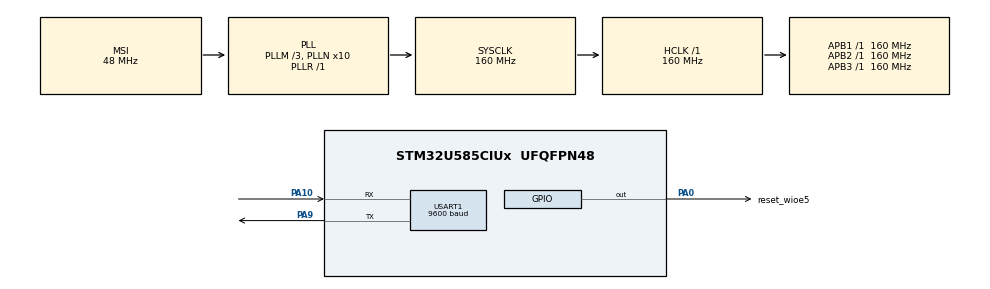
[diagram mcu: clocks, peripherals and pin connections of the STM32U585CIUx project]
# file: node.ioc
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CORTEX_M33_NS.userName=CORTEX_M33
Mcu.Family=STM32U5
Mcu.Name=STM32U585CIUx
Mcu.Package=UFQFPN48
NVIC.PriorityGroup=NVIC_PRIORITYGROUP_4
NVIC.RTC_IRQn=true\:0\:0\:false\:false\:true\:true\:true\:true
NVIC.USART1_IRQn=true\:0\:0\:false\:false\:true\:true\:true\:true
PA0.GPIO_Label=reset_wioe5
PA0.GPIO_ModeDefaultOutputPP=GPIO_MODE_OUTPUT_OD
PA0.GPIO_PuPd=GPIO_NOPULL
PA0.PinState=GPIO_PIN_RESET
PA0.Signal=GPIO_Output
PA10.GPIO_PuPd=GPIO_PULLUP
PA10.Mode=Asynchronous
PA10.Signal=USART1_RX
PA13\ (JTMS/SWDIO).Mode=Serial_Wire
PA13\ (JTMS/SWDIO).Signal=DEBUG_JTMS-SWDIO
PA14\ (JTCK/SWCLK).Mode=Serial_Wire
PA14\ (JTCK/SWCLK).Signal=DEBUG_JTCK-SWCLK
PA9.GPIO_PuPd=GPIO_PULLUP
PA9.Mode=Asynchronous
PA9.Signal=USART1_TX
PC14-OSC32_IN\ (PC14).Mode=LSE-External-Oscillator
PC14-OSC32_IN\ (PC14).Signal=RCC_OSC32_IN
PC15-OSC32_OUT\ (PC15).Mode=LSE-External-Oscillator
PC15-OSC32_OUT\ (PC15).Signal=RCC_OSC32_OUT
PH0-OSC_IN\ (PH0).Mode=HSE-External-Oscillator
PH0-OSC_IN\ (PH0).Signal=RCC_OSC_IN
PH1-OSC_OUT\ (PH1).Mode=HSE-External-Oscillator
PH1-OSC_OUT\ (PH1).Signal=RCC_OSC_OUT
ProjectManager.HeapSize=0x200
ProjectManager.StackSize=0x400
ProjectManager.TargetToolchain=CMake
RCC.ADCFreq_Value=16000000
RCC.AHBFreq_Value=160000000
RCC.APB1Freq_Value=160000000
RCC.APB1TimFreq_Value=160000000
RCC.APB2Freq_Value=160000000
RCC.APB2TimFreq_Value=160000000
RCC.APB3Freq_Value=160000000
RCC.CortexFreq_Value=160000000
RCC.EPOD_VALUE=48000000
RCC.HCLKFreq_Value=160000000
RCC.HSE_VALUE=16000000
RCC.HSI48_VALUE=48000000
RCC.HSI_VALUE=16000000
RCC.LSIDIV_VALUE=32000
RCC.MSIClockRange=RCC_MSIRANGE_0
RCC.MSI_VALUE=48000000
RCC.PLL1R=1
RCC.PLL2FRACN=0
RCC.PLL3FRACN=0
RCC.PLLFRACN=0
RCC.PLLM=3
RCC.PLLN=10
RCC.RTCClockSelection=RCC_RTCCLKSOURCE_LSE
RCC.SYSCLKFreq_VALUE=160000000
RCC.SYSCLKSource=RCC_SYSCLKSOURCE_PLLCLK
RCC.USBFreq_Value=48000000
RCC.VCOOutputFreq_Value=160000000
USART1.BaudRate=9600
USART1.VirtualMode-Asynchronous=VM_ASYNC
VP_LPBAMQUEUE_VS_QUEUE.Mode=QUEUEMODE
VP_LPBAM_VS_SIG1.Mode=SmartRun
VP_LPBAM_VS_SIG4.Mode=LPDMA1
VP_MEMORYMAP_VS_MEMORYMAP.Mode=CurAppReg
VP_PWR_VS_SECSignals.Mode=Security/Privilege
VP_RTC_VS_RTC_Activate.Mode=RTC_Enabled
VP_RTC_VS_RTC_WakeUp_intern.Mode=WakeUp
board=custom

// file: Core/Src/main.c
/* USER CODE BEGIN Header */
/**
  ******************************************************************************
  * @file           : main.c
  * @brief          : Main program body
  ******************************************************************************
  * @attention
  *
  * Copyright (c) 2026 STMicroelectronics.
  * All rights reserved.
  *
  * This software is licensed under terms that can be found in the LICENSE file
  * in the root directory of this software component.
  * If no LICENSE file comes with this software, it is provided AS-IS.
  *
  ******************************************************************************
  */
/* USER CODE END Header */
#include "main.h"

/* USER CODE BEGIN Includes */
#include "app_node.h"
/* USER CODE END Includes */

RTC_HandleTypeDef hrtc;

UART_HandleTypeDef huart1;

void SystemClock_Config(void);
static void MX_GPIO_Init(void);
static void MX_USART1_UART_Init(void);
static void MX_RTC_Init(void);

int main(void)
{

  /* MCU Configuration--------------------------------------------------------*/

  /* Reset of all peripherals, Initializes the Flash interface and the Systick. */
  HAL_Init();

  /* Configure the system clock */
  SystemClock_Config();

  /* Initialize all configured peripherals */
  MX_GPIO_Init();
  MX_USART1_UART_Init();
  MX_RTC_Init();
  /* USER CODE BEGIN 2 */
  app_node_init(&huart1);
  /* USER CODE END 2 */

  /* Infinite loop */
  while (1)
  {

    /* USER CODE BEGIN 3 */
    app_node_process();
  }
  /* USER CODE END 3 */
}

void SystemClock_Config(void)
{
  RCC_OscInitTypeDef RCC_OscInitStruct = {0};
  RCC_ClkInitTypeDef RCC_ClkInitStruct = {0};

  /** Configure the main internal regulator output voltage
  */
  if (HAL_PWREx_ControlVoltageScaling(PWR_REGULATOR_VOLTAGE_SCALE1) != HAL_OK)
  {
    Error_Handler();
  }

  /** Configure LSE Drive Capability
  */
  HAL_PWR_EnableBkUpAccess();
  __HAL_RCC_LSEDRIVE_CONFIG(RCC_LSEDRIVE_LOW);

  /** Initializes the CPU, AHB and APB buses clocks
  */
  RCC_OscInitStruct.OscillatorType = RCC_OSCILLATORTYPE_LSE|RCC_OSCILLATORTYPE_MSI;
  RCC_OscInitStruct.LSEState = RCC_LSE_ON;
  RCC_OscInitStruct.MSIState = RCC_MSI_ON;
  RCC_OscInitStruct.MSICalibrationValue = RCC_MSICALIBRATION_DEFAULT;
  RCC_OscInitStruct.MSIClockRange = RCC_MSIRANGE_0;
  RCC_OscInitStruct.PLL.PLLState = RCC_PLL_ON;
  RCC_OscInitStruct.PLL.PLLSource = RCC_PLLSOURCE_MSI;
  RCC_OscInitStruct.PLL.PLLMBOOST = RCC_PLLMBOOST_DIV4;
  RCC_OscInitStruct.PLL.PLLM = 3;
  RCC_OscInitStruct.PLL.PLLN = 10;
  RCC_OscInitStruct.PLL.PLLP = 2;
  RCC_OscInitStruct.PLL.PLLQ = 2;
  RCC_OscInitStruct.PLL.PLLR = 1;
  RCC_OscInitStruct.PLL.PLLRGE = RCC_PLLVCIRANGE_1;
  RCC_OscInitStruct.PLL.PLLFRACN = 0;
  if (HAL_RCC_OscConfig(&RCC_OscInitStruct) != HAL_OK)
  {
    Error_Handler();
  }

  /** Initializes the CPU, AHB and APB buses clocks
  */
  RCC_ClkInitStruct.ClockType = RCC_CLOCKTYPE_HCLK|RCC_CLOCKTYPE_SYSCLK
                              |RCC_CLOCKTYPE_PCLK1|RCC_CLOCKTYPE_PCLK2
                              |RCC_CLOCKTYPE_PCLK3;
  RCC_ClkInitStruct.SYSCLKSource = RCC_SYSCLKSOURCE_PLLCLK;
  RCC_ClkInitStruct.AHBCLKDivider = RCC_SYSCLK_DIV1;
  RCC_ClkInitStruct.APB1CLKDivider = RCC_HCLK_DIV1;
  RCC_ClkInitStruct.APB2CLKDivider = RCC_HCLK_DIV1;
  RCC_ClkInitStruct.APB3CLKDivider = RCC_HCLK_DIV1;

  if (HAL_RCC_ClockConfig(&RCC_ClkInitStruct, FLASH_LATENCY_4) != HAL_OK)
  {
    Error_Handler();
  }
}

static void MX_RTC_Init(void)
{

  RTC_PrivilegeStateTypeDef privilegeState = {0};

  /** Initialize RTC Only
  */
  hrtc.Instance = RTC;
  hrtc.Init.HourFormat = RTC_HOURFORMAT_24;
  hrtc.Init.AsynchPrediv = 127;
  hrtc.Init.SynchPrediv = 255;
  hrtc.Init.OutPut = RTC_OUTPUT_DISABLE;
  hrtc.Init.OutPutRemap = RTC_OUTPUT_REMAP_NONE;
  hrtc.Init.OutPutPolarity = RTC_OUTPUT_POLARITY_HIGH;
  hrtc.Init.OutPutType = RTC_OUTPUT_TYPE_OPENDRAIN;
  hrtc.Init.OutPutPullUp = RTC_OUTPUT_PULLUP_NONE;
  hrtc.Init.BinMode = RTC_BINARY_NONE;
  if (HAL_RTC_Init(&hrtc) != HAL_OK)
  {
    Error_Handler();
  }
  privilegeState.rtcPrivilegeFull = RTC_PRIVILEGE_FULL_NO;
  privilegeState.backupRegisterPrivZone = RTC_PRIVILEGE_BKUP_ZONE_NONE;
  privilegeState.backupRegisterStartZone2 = RTC_BKP_DR0;
  privilegeState.backupRegisterStartZone3 = RTC_BKP_DR0;
  if (HAL_RTCEx_PrivilegeModeSet(&hrtc, &privilegeState) != HAL_OK)
  {
    Error_Handler();
  }

  /** Enable the WakeUp
  */
  if (HAL_RTCEx_SetWakeUpTimer_IT(&hrtc, 0, RTC_WAKEUPCLOCK_RTCCLK_DIV16, 0) != HAL_OK)
  {
    Error_Handler();
  }
  /* USER CODE BEGIN RTC_Init 2 */
  /* CubeMX starts the wakeup timer with counter 0 at RTCCLK/16 (an interrupt
   * every ~0.5 ms). The app programs it only right before Stop 2. */
  if (HAL_RTCEx_DeactivateWakeUpTimer(&hrtc) != HAL_OK)
  {
    Error_Handler();
  }
  /* USER CODE END RTC_Init 2 */

}

static void MX_USART1_UART_Init(void)
{

  huart1.Instance = USART1;
  huart1.Init.BaudRate = 9600;
  huart1.Init.WordLength = UART_WORDLENGTH_8B;
  huart1.Init.StopBits = UART_STOPBITS_1;
  huart1.Init.Parity = UART_PARITY_NONE;
  huart1.Init.Mode = UART_MODE_TX_RX;
  huart1.Init.HwFlowCtl = UART_HWCONTROL_NONE;
  huart1.Init.OverSampling = UART_OVERSAMPLING_16;
  huart1.Init.OneBitSampling = UART_ONE_BIT_SAMPLE_DISABLE;
  huart1.Init.ClockPrescaler = UART_PRESCALER_DIV1;
  huart1.AdvancedInit.AdvFeatureInit = UART_ADVFEATURE_NO_INIT;
  if (HAL_UART_Init(&huart1) != HAL_OK)
  {
    Error_Handler();
  }
  if (HAL_UARTEx_SetTxFifoThreshold(&huart1, UART_TXFIFO_THRESHOLD_1_8) != HAL_OK)
  {
    Error_Handler();
  }
  if (HAL_UARTEx_SetRxFifoThreshold(&huart1, UART_RXFIFO_THRESHOLD_1_8) != HAL_OK)
  {
    Error_Handler();
  }
  if (HAL_UARTEx_DisableFifoMode(&huart1) != HAL_OK)
  {
    Error_Handler();
  }

}

static void MX_GPIO_Init(void)
{
  GPIO_InitTypeDef GPIO_InitStruct = {0};

  /* GPIO Ports Clock Enable */
  __HAL_RCC_GPIOC_CLK_ENABLE();
  __HAL_RCC_GPIOH_CLK_ENABLE();
  __HAL_RCC_GPIOA_CLK_ENABLE();

  /*Configure GPIO pin Output Level */
  HAL_GPIO_WritePin(reset_wioe5_GPIO_Port, reset_wioe5_Pin, GPIO_PIN_RESET);

  /*Configure GPIO pin : reset_wioe5_Pin */
  GPIO_InitStruct.Pin = reset_wioe5_Pin;
  GPIO_InitStruct.Mode = GPIO_MODE_OUTPUT_OD;
  GPIO_InitStruct.Pull = GPIO_NOPULL;
  GPIO_InitStruct.Speed = GPIO_SPEED_FREQ_LOW;
  HAL_GPIO_Init(reset_wioe5_GPIO_Port, &GPIO_InitStruct);

}

void Error_Handler(void)
{
  __disable_irq();
  while (1)
  {
  }
}
